# HK32L0xx register map
Vendor: HKMicroChip Ltd.; Series: HK32L0xx; File version: 1.3
CPU: CM0 r0p0, little endian, no MPU, no FPU, 3 interrupt priority bits
Registers are 32-bit, read-write, reset 0x0 unless marked. A register's access mark holds for its fields unless they carry their own. Offsets are from the block's base; [hi:lo] are bit positions; {n}, {i} and the like mark numbered series.

## DVSQ
Base 0x40030000
0x00 DIVIDEND
0x04 DIVISOR
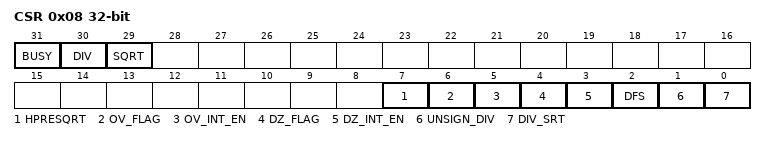
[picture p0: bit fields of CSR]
0x08 CSR access per field
  [31] BUSY ro — Busy bit
  [30] DIV ro — Divide operation flag
  [29] SQRT ro — Square-root operation flag
  [7] HPRESQRT rw — High precision square-root operation selection
  [6] OV_FLAG rw — Sign divide overflow flag
  [5] OV_INT_EN rw — Sign divide overflow interrupt enable
  [4] DZ_FLAG rw — Zero divisor flag
  [3] DZ_INT_EN rw — Zero divisor interrupt enable
  [2] DFS rw — Divide operation fast start disable
  [1] UNSIGN_DIV rw — Unsign divide operation enable
  [0] DIV_SRT rw — Divide operation start
0x0C RADICAND
0x10 RES
  [31:0] RESULT
0x14 REMAINDER

## USB
Base 0x40005C00
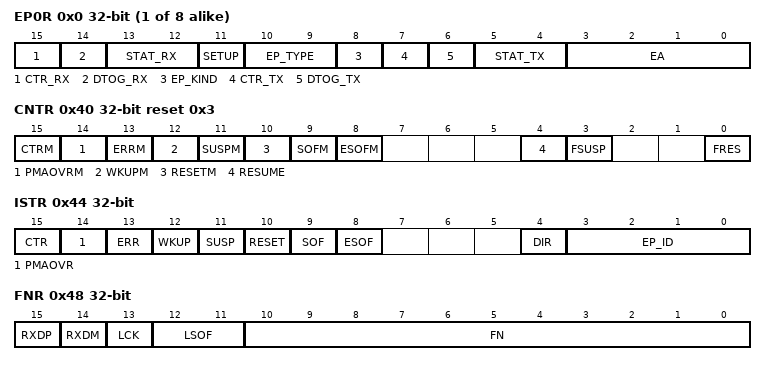
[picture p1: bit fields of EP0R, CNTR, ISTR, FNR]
{0x0+4i} EP{i}R access per field (i=0..7)
  [15] CTR_RX rw — Correct Transfer for reception
  [14] DTOG_RX rw — Data Toggle, for reception transfers
  [13:12] STAT_RX rw — Status bits,for reception transfers
  [11] SETUP ro — Setup transaction completed
  [10:9] EP_TYPE rw — Endpoint type
  [8] EP_KIND rw — Endpoint kind
  [7] CTR_TX rw — Correct Transfer for transmission
  [6] DTOG_TX rw — Data Toggle, for transmission transfers
  [5:4] STAT_TX rw — Status bits, for transmission transfers
  [3:0] EA rw — Endpoint address
0x40 CNTR reset 0x3
  [15] CTRM — Correct transfer interrupt mask
  [14] PMAOVRM — Packet memory area over/underrun interrupt mask
  [13] ERRM — Error interrupt mask
  [12] WKUPM — Wakeup interrupt mask
  [11] SUSPM — Suspend mode interrupt mask
  [10] RESETM — USB reset interrupt mask
  [9] SOFM — Start of frame interrupt mask
  [8] ESOFM — Expected start of frame interrupt mask
  [4] RESUME — Resume request
  [3] FSUSP — Force suspend
  [0] FRES — Force USB reset
0x44 ISTR access per field
  [15] CTR rw — Correct transfer
  [14] PMAOVR rw — Packet memory area over/underrun
  [13] ERR rw — Error
  [12] WKUP rw — Wakeup request
  [11] SUSP rw — Suspend mode request
  [10] RESET rw — USB reset request
  [9] SOF rw — Start of frame
  [8] ESOF rw — Expected start of frame
  [4] DIR ro — Direction of transaction
  [3:0] EP_ID ro — Endpoint Identifier
0x48 FNR ro
  [15] RXDP — Receive data+line status
  [14] RXDM — Receive data-line status
  [13] LCK — Locked
  [12:11] LSOF — Lost SOF
  [10:0] FN — Frame number
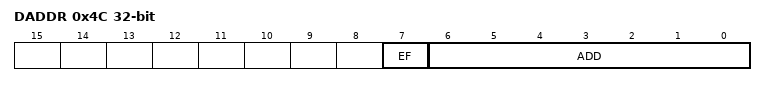
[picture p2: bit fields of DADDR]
0x4C DADDR
  [7] EF — Enable function
  [6:0] ADD — Device address
0x50 BTABLE
  [15:3] BTABLE — Buffer table

## CLU
Base 0x40006800
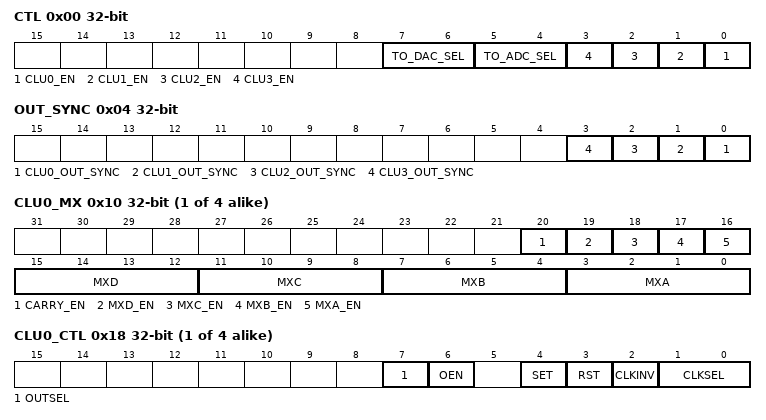
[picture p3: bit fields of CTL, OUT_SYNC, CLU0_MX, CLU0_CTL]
0x00 CTL
  [7:6] TO_DAC_SEL — Select CLU channel to trigger DAC
  [5:4] TO_ADC_SEL — Selecte CLU channel to trigger ADC
  [n] CLU{n}_EN (n=0..3) — Configurable logic unit {n} enable
0x04 OUT_SYNC ro
  [n] CLU{n}_OUT_SYNC (n=0..3) — Configurable logic unit {n} synchronous output
{0x10+0x10*i} CLU{i}_MX (i=0..3)
  [20] CARRY_EN — Enable carry in
  [19] MXD_EN — Enable CLUx multiplexer D
  [18] MXC_EN — Enable CLUx multiplexer C
  [17] MXB_EN — Enable CLUx multiplexer B
  [16] MXA_EN — Enable CLUx multiplexer A
  [15:12] MXD — Select the input source to CLUx multiplex channel D
  [11:8] MXC — Select the input source to CLUx multiplex channel C
  [7:4] MXB — Select the input source to CLUx multiplex channel B
  [3:0] MXA — Select the input source to CLUx multiplex channel A
{0x14+0x10*i} CLU{i}_FN (i=0..3)
  [31:0] CLUx_FN — Function selection for CLUx
{0x18+0x10*i} CLU{i}_CTL (i=0..3)
  [7] OUTSEL — CLUx output selection
  [6] OEN — CLU port output enable
  [4] SET — Set CLUx
  [3] RST — Reset CLUx
  [2] CLKINV — CLUx D flip-flop Clock Invert
  [1:0] CLKSEL — CLUx D flip-flop Clock Selection

## ADC
Base 0x40012400
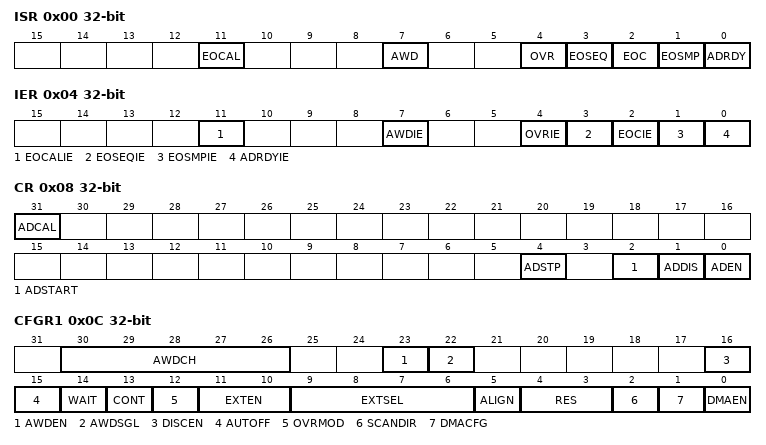
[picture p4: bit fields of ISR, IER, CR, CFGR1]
0x00 ISR
  [11] EOCAL — End of calibration flag
  [7] AWD — Analog watchdog flag
  [4] OVR — ADC overrun
  [3] EOSEQ — End of sequence flag
  [2] EOC — End of conversion flag
  [1] EOSMP — End of sampling flag
  [0] ADRDY — ADC ready
0x04 IER
  [11] EOCALIE — End of calibration interrupt enable
  [7] AWDIE — Analog watchdog interrupt enable
  [4] OVRIE — Overrun interrupt enable
  [3] EOSEQIE — End of conversion sequence interrupt enable
  [2] EOCIE — End of conversion interrupt enable
  [1] EOSMPIE — End of sampling interrupt enable
  [0] ADRDYIE — ADC ready interrupt enable
0x08 CR
  [31] ADCAL — ADC calibration
  [4] ADSTP — ADC stop conversion command
  [2] ADSTART — ADC start conversion command
  [1] ADDIS — ADC disable command
  [0] ADEN — ADC enable command
0x0C CFGR1
  [30:26] AWDCH — Analog watchdog channel selection
  [23] AWDEN — Analog watchdog enable
  [22] AWDSGL — Enable the watchdog on a single channel or on all channels
  [16] DISCEN — Discontinuous mode
  [15] AUTOFF — Auto-off mode
  [14] WAIT — Wait conversion mode
  [13] CONT — Single/continuous conversion mode
  [12] OVRMOD — Overrun management mode
  [11:10] EXTEN — External trigger enable and polarity selection
  [9:6] EXTSEL — External trigger selection
  [5] ALIGN — Data alignment
  [4:3] RES — Data resolution
  [2] SCANDIR — Scan sequence direction
  [1] DMACFG — Direct memory access configuration
  [0] DMAEN — Direct memory access enable
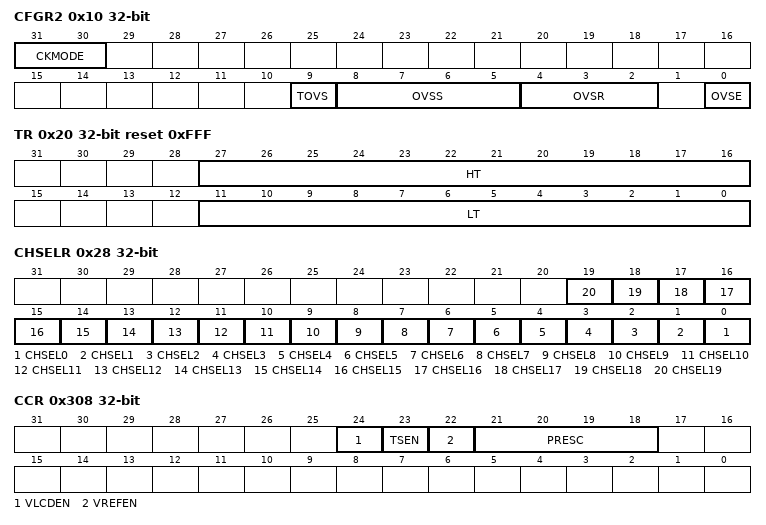
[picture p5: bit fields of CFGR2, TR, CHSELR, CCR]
0x10 CFGR2
  [31:30] CKMODE — ADC clock mode
  [9] TOVS — Triggered Oversampling
  [8:5] OVSS — Oversampling shift
  [4:2] OVSR — Oversampling ratio
  [0] OVSE — Oversampler Enable
0x14 SMPR
  [2:0] SMP — Sampling time selection
0x20 TR reset 0xFFF
  [27:16] HT — Analog watchdog higher threshold
  [11:0] LT — Analog watchdog lower threshold
0x28 CHSELR
  [n] CHSEL{n} (n=0..19) — Channel-x selection
0x40 DR ro
  [15:0] DATA — Converted data
0x308 CCR
  [24] VLCDEN — VLCD enable
  [23] TSEN — Temperature sensor enable
  [22] VREFEN — VREFINT enable
  [21:18] PRESC — ADC prescaler
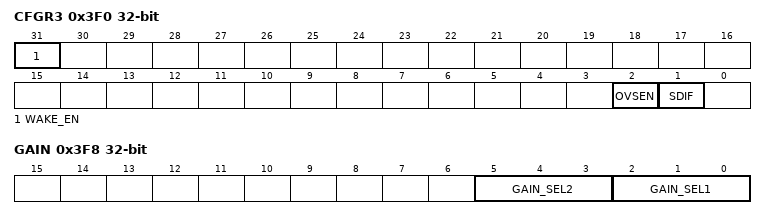
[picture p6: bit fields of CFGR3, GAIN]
0x3F0 CFGR3
  [31] WAKE_EN — Analog watchdog weak up enable
  [2] OVSEN — Oversampling function enable
  [1] SDIF — The differential input enable
0x3F8 GAIN
  [5:3] GAIN_SEL2 — Gain Factor 2 configuration
  [2:0] GAIN_SEL1 — Gain Factor 1 configuration
